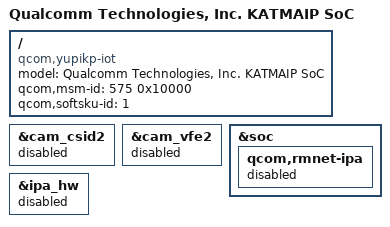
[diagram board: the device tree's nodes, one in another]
#include "katmai.dtsi"

/ {
	model = "Qualcomm Technologies, Inc. KATMAIP SoC";
	compatible = "qcom,yupikp-iot";
	qcom,msm-id = <575 0x10000>;
	qcom,softsku-id = <1>;
};

&cam_csid2 {
	status = "disabled";
};

&cam_vfe2 {
	status = "disabled";
};

&soc {
	qcom,rmnet-ipa {
		status = "disabled";
	};
};

&ipa_hw {
	status = "disabled";
};
